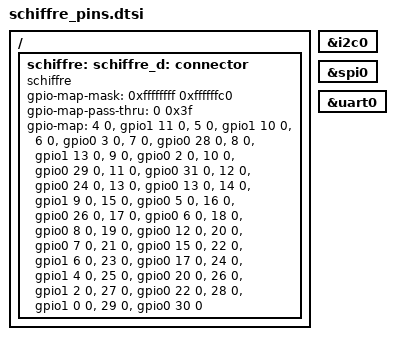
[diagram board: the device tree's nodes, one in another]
/*
 * Copyright (c) 2020 The ZMK Contributors
 *
 * SPDX-License-Identifier: MIT
 */


/ {
	schiffre: connector {
		compatible = "schiffre";
		#gpio-cells = <2>;
		gpio-map-mask = <0xffffffff 0xffffffc0>;
		gpio-map-pass-thru = <0 0x3f>;
		gpio-map
			= < 4 0 &gpio1 11 0>  /* FCC 04 */
			, < 5 0 &gpio1 10 0>  /* FCC 05 */
			, < 6 0 &gpio0  3 0>  /* FCC 06 */
			, < 7 0 &gpio0 28 0>  /* FCC 07 */
			, < 8 0 &gpio1 13 0>  /* FCC 08 */
			, < 9 0 &gpio0  2 0>  /* FCC 09 */
			, <10 0 &gpio0 29 0>  /* FCC 10 */
			, <11 0 &gpio0 31 0>  /* FCC 11 */
			, <12 0 &gpio0 24 0>  /* FCC 12 */
			, <13 0 &gpio0 13 0>  /* FCC 13 */
			, <14 0 &gpio1  9 0>  /* FCC 14 */
			, <15 0 &gpio0  5 0>  /* FCC 15 */
			, <16 0 &gpio0 26 0>  /* FCC 16 */
			, <17 0 &gpio0  6 0>  /* FCC 17 */
			, <18 0 &gpio0  8 0>  /* FCC 18 */
			, <19 0 &gpio0 12 0>  /* FCC 19 */
			, <20 0 &gpio0  7 0>  /* FCC 20 */
			, <21 0 &gpio0 15 0>  /* FCC 21 */
			, <22 0 &gpio1  6 0>  /* FCC 22 */
			, <23 0 &gpio0 17 0>  /* FCC 23 */
			, <24 0 &gpio1  4 0>  /* FCC 24 */
			, <25 0 &gpio0 20 0>  /* FCC 25 */
			, <26 0 &gpio1  2 0>  /* FCC 26 */
			, <27 0 &gpio0 22 0>  /* FCC 27 */
			, <28 0 &gpio1  0 0>  /* FCC 28 */
			, <29 0 &gpio0 30 0>  /* FCC 29 */
			;
	};

};


schiffre_d: &schiffre {};
schiffre_i2c: &i2c0 {};
schiffre_spi: &spi0 {};
schiffre_serial: &uart0 {};
